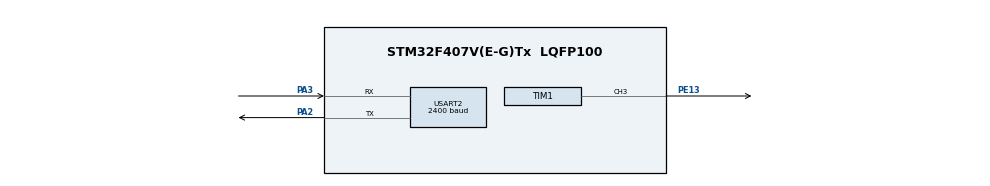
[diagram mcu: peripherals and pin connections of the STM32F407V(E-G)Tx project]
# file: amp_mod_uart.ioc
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Mcu.Family=STM32F4
Mcu.Name=STM32F407V(E-G)Tx
Mcu.Package=LQFP100
NVIC.PriorityGroup=NVIC_PRIORITYGROUP_4
NVIC.TIM1_UP_TIM10_IRQn=true\:0\:0\:true\:false\:true\:true\:true\:true
NVIC.USART2_IRQn=true\:3\:0\:true\:false\:true\:true\:true\:true
PA2.Mode=Asynchronous
PA2.Signal=USART2_TX
PA3.Mode=Asynchronous
PA3.Signal=USART2_RX
PE13.GPIO_Speed=GPIO_SPEED_FREQ_VERY_HIGH
PE13.Signal=S_TIM1_CH3
ProjectManager.HeapSize=0x200
ProjectManager.StackSize=0x400
ProjectManager.TargetToolchain=STM32CubeIDE
RCC.48MHZClocksFreq_Value=84000000
RCC.AHBFreq_Value=168000000
RCC.APB1CLKDivider=RCC_HCLK_DIV4
RCC.APB1Freq_Value=42000000
RCC.APB1TimFreq_Value=84000000
RCC.APB2CLKDivider=RCC_HCLK_DIV2
RCC.APB2Freq_Value=84000000
RCC.APB2TimFreq_Value=168000000
RCC.CortexFreq_Value=168000000
RCC.HCLKFreq_Value=168000000
RCC.HSE_VALUE=25000000
RCC.HSI_VALUE=16000000
RCC.LSE_VALUE=32768
RCC.PLLM=8
RCC.PLLN=168
RCC.SYSCLKFreq_VALUE=168000000
RCC.SYSCLKSource=RCC_SYSCLKSOURCE_PLLCLK
RCC.VCOOutputFreq_Value=336000000
SH.S_TIM1_CH3.0=TIM1_CH3,PWM Generation3 CH3
TIM1.AutoReloadPreload=TIM_AUTORELOAD_PRELOAD_ENABLE
TIM1.Channel-PWM\ Generation3\ CH3=TIM_CHANNEL_3
TIM1.CounterMode=TIM_COUNTERMODE_UP
TIM1.OCFastMode_PWM-PWM\ Generation3\ CH3=TIM_OCFAST_ENABLE
TIM1.Period=23
TIM1.Prescaler=6
TIM1.Pulse-PWM\ Generation3\ CH3=11
TIM1.RepetitionCounter=0
TIM1.TIM_MasterOutputTrigger=TIM_TRGO_RESET
TIM1.TIM_MasterSlaveMode=TIM_MASTERSLAVEMODE_DISABLE
USART2.BaudRate=2400
USART2.VirtualMode=VM_ASYNC
VP_TIM1_VS_ClockSourceINT.Mode=Internal
board=custom

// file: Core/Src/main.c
/* USER CODE BEGIN Header */
/**
  ******************************************************************************
  * @file           : main.c
  * @brief          : Main program body
  ******************************************************************************
  * @attention
  *
  * Copyright (c) 2023 STMicroelectronics.
  * All rights reserved.
  *
  * This software is licensed under terms that can be found in the LICENSE file
  * in the root directory of this software component.
  * If no LICENSE file comes with this software, it is provided AS-IS.
  *
  ******************************************************************************
  */
/* USER CODE END Header */
#include "main.h"

void SystemClock_Config(void);
static void MX_GPIO_Init(void);
static void MX_USART2_UART_Init(void);
static void MX_TIM1_Init(void);

/* USER CODE BEGIN 0 */

int32_t TIM_PERIOD_CNT_100=24;
int32_t TIM_PERIOD_CNT_50=11;
int32_t checkUSART=0;

void TIM1_Callback(void){
  if(LL_GPIO_IsInputPinSet(GPIOA, LL_GPIO_PIN_2)){
    TIM1->CCR3=TIM_PERIOD_CNT_100;
  }else{
	TIM1->CCR3=TIM_PERIOD_CNT_50;
  }
  if(LL_TIM_IsActiveFlag_UPDATE(TIM1)){
    LL_TIM_ClearFlag_UPDATE(TIM1);
  }
}
void  USART2_TX_Callback(void){
  LL_USART_ClearFlag_TC(USART2);
  checkUSART=1;
}

/* USER CODE END 0 */

int main(void)
{
  /* USER CODE BEGIN 1 */
	uint8_t x=0;
  /* USER CODE END 1 */

  /* MCU Configuration--------------------------------------------------------*/

  /* Reset of all peripherals, Initializes the Flash interface and the Systick. */
  LL_APB2_GRP1_EnableClock(LL_APB2_GRP1_PERIPH_SYSCFG);
  LL_APB1_GRP1_EnableClock(LL_APB1_GRP1_PERIPH_PWR);

  /* System interrupt init*/
  NVIC_SetPriorityGrouping(NVIC_PRIORITYGROUP_4);

  /* Configure the system clock */
  SystemClock_Config();

  /* Initialize all configured peripherals */
  MX_GPIO_Init();
  MX_USART2_UART_Init();
  MX_TIM1_Init();
  /* USER CODE BEGIN 2 */

  LL_TIM_EnableARRPreload(TIM1);//Enable automatic loading (ARR) preload
  LL_TIM_OC_EnableFast(TIM1, LL_TIM_CHANNEL_CH3);//Enable fast mode for the output channel
  LL_TIM_CC_EnableChannel(TIM1,LL_TIM_CHANNEL_CH3); //Enable capture/compare channel
  LL_TIM_EnableIT_UPDATE(TIM1);//Enable interrupt
  LL_TIM_EnableAllOutputs(TIM1);//Enable PWM output
  LL_TIM_EnableCounter(TIM1);

  __enable_irq ();
  /* USER CODE END 2 */

  /* Infinite loop */
  /* USER CODE BEGIN WHILE */
  while (1)
  {
	if(checkUSART){
	  checkUSART=0;
	  x++;
	  LL_mDelay(1000);
	}
    LL_USART_TransmitData8(USART2, x);

    /* USER CODE END WHILE */

  }
}

void SystemClock_Config(void)
{
  LL_FLASH_SetLatency(LL_FLASH_LATENCY_5);
  while(LL_FLASH_GetLatency()!= LL_FLASH_LATENCY_5)
  {
  }
  LL_PWR_SetRegulVoltageScaling(LL_PWR_REGU_VOLTAGE_SCALE1);
  LL_RCC_HSI_SetCalibTrimming(16);
  LL_RCC_HSI_Enable();

   /* Wait till HSI is ready */
  while(LL_RCC_HSI_IsReady() != 1)
  {

  }
  LL_RCC_PLL_ConfigDomain_SYS(LL_RCC_PLLSOURCE_HSI, LL_RCC_PLLM_DIV_8, 168, LL_RCC_PLLP_DIV_2);
  LL_RCC_PLL_Enable();

   /* Wait till PLL is ready */
  while(LL_RCC_PLL_IsReady() != 1)
  {

  }
  LL_RCC_SetAHBPrescaler(LL_RCC_SYSCLK_DIV_1);
  LL_RCC_SetAPB1Prescaler(LL_RCC_APB1_DIV_4);
  LL_RCC_SetAPB2Prescaler(LL_RCC_APB2_DIV_2);
  LL_RCC_SetSysClkSource(LL_RCC_SYS_CLKSOURCE_PLL);

   /* Wait till System clock is ready */
  while(LL_RCC_GetSysClkSource() != LL_RCC_SYS_CLKSOURCE_STATUS_PLL)
  {

  }
  LL_Init1msTick(168000000);
  LL_SetSystemCoreClock(168000000);
}

static void MX_TIM1_Init(void)
{

  /* USER CODE BEGIN TIM1_Init 0 */
	//TIM1->CCR1=TIM1->ARR/2;

  /* USER CODE END TIM1_Init 0 */

  LL_TIM_InitTypeDef TIM_InitStruct = {0};
  LL_TIM_OC_InitTypeDef TIM_OC_InitStruct = {0};
  LL_TIM_BDTR_InitTypeDef TIM_BDTRInitStruct = {0};

  LL_GPIO_InitTypeDef GPIO_InitStruct = {0};

  /* Peripheral clock enable */
  LL_APB2_GRP1_EnableClock(LL_APB2_GRP1_PERIPH_TIM1);

  /* TIM1 interrupt Init */
  NVIC_SetPriority(TIM1_UP_TIM10_IRQn, NVIC_EncodePriority(NVIC_GetPriorityGrouping(),0, 0));
  NVIC_EnableIRQ(TIM1_UP_TIM10_IRQn);

  TIM_InitStruct.Prescaler = 6;
  TIM_InitStruct.CounterMode = LL_TIM_COUNTERMODE_UP;
  TIM_InitStruct.Autoreload = 23;
  TIM_InitStruct.ClockDivision = LL_TIM_CLOCKDIVISION_DIV1;
  TIM_InitStruct.RepetitionCounter = 0;
  LL_TIM_Init(TIM1, &TIM_InitStruct);
  LL_TIM_EnableARRPreload(TIM1);
  LL_TIM_SetClockSource(TIM1, LL_TIM_CLOCKSOURCE_INTERNAL);
  LL_TIM_OC_EnablePreload(TIM1, LL_TIM_CHANNEL_CH3);
  TIM_OC_InitStruct.OCMode = LL_TIM_OCMODE_PWM1;
  TIM_OC_InitStruct.OCState = LL_TIM_OCSTATE_DISABLE;
  TIM_OC_InitStruct.OCNState = LL_TIM_OCSTATE_DISABLE;
  TIM_OC_InitStruct.CompareValue = 11;
  TIM_OC_InitStruct.OCPolarity = LL_TIM_OCPOLARITY_HIGH;
  TIM_OC_InitStruct.OCNPolarity = LL_TIM_OCPOLARITY_HIGH;
  TIM_OC_InitStruct.OCIdleState = LL_TIM_OCIDLESTATE_LOW;
  TIM_OC_InitStruct.OCNIdleState = LL_TIM_OCIDLESTATE_LOW;
  LL_TIM_OC_Init(TIM1, LL_TIM_CHANNEL_CH3, &TIM_OC_InitStruct);
  LL_TIM_OC_EnableFast(TIM1, LL_TIM_CHANNEL_CH3);
  LL_TIM_SetTriggerOutput(TIM1, LL_TIM_TRGO_RESET);
  LL_TIM_DisableMasterSlaveMode(TIM1);
  TIM_BDTRInitStruct.OSSRState = LL_TIM_OSSR_DISABLE;
  TIM_BDTRInitStruct.OSSIState = LL_TIM_OSSI_DISABLE;
  TIM_BDTRInitStruct.LockLevel = LL_TIM_LOCKLEVEL_OFF;
  TIM_BDTRInitStruct.DeadTime = 0;
  TIM_BDTRInitStruct.BreakState = LL_TIM_BREAK_DISABLE;
  TIM_BDTRInitStruct.BreakPolarity = LL_TIM_BREAK_POLARITY_HIGH;
  TIM_BDTRInitStruct.AutomaticOutput = LL_TIM_AUTOMATICOUTPUT_DISABLE;
  LL_TIM_BDTR_Init(TIM1, &TIM_BDTRInitStruct);
  LL_AHB1_GRP1_EnableClock(LL_AHB1_GRP1_PERIPH_GPIOE);
  /**TIM1 GPIO Configuration
  PE13   ------> TIM1_CH3
  */
  GPIO_InitStruct.Pin = LL_GPIO_PIN_13;
  GPIO_InitStruct.Mode = LL_GPIO_MODE_ALTERNATE;
  GPIO_InitStruct.Speed = LL_GPIO_SPEED_FREQ_VERY_HIGH;
  GPIO_InitStruct.OutputType = LL_GPIO_OUTPUT_PUSHPULL;
  GPIO_InitStruct.Pull = LL_GPIO_PULL_NO;
  GPIO_InitStruct.Alternate = LL_GPIO_AF_1;
  LL_GPIO_Init(GPIOE, &GPIO_InitStruct);

}

static void MX_USART2_UART_Init(void)
{

  LL_USART_InitTypeDef USART_InitStruct = {0};

  LL_GPIO_InitTypeDef GPIO_InitStruct = {0};

  /* Peripheral clock enable */
  LL_APB1_GRP1_EnableClock(LL_APB1_GRP1_PERIPH_USART2);

  LL_AHB1_GRP1_EnableClock(LL_AHB1_GRP1_PERIPH_GPIOA);
  /**USART2 GPIO Configuration
  PA2   ------> USART2_TX
  PA3   ------> USART2_RX
  */
  GPIO_InitStruct.Pin = LL_GPIO_PIN_2|LL_GPIO_PIN_3;
  GPIO_InitStruct.Mode = LL_GPIO_MODE_ALTERNATE;
  GPIO_InitStruct.Speed = LL_GPIO_SPEED_FREQ_VERY_HIGH;
  GPIO_InitStruct.OutputType = LL_GPIO_OUTPUT_PUSHPULL;
  GPIO_InitStruct.Pull = LL_GPIO_PULL_NO;
  GPIO_InitStruct.Alternate = LL_GPIO_AF_7;
  LL_GPIO_Init(GPIOA, &GPIO_InitStruct);

  /* USART2 interrupt Init */
  NVIC_SetPriority(USART2_IRQn, NVIC_EncodePriority(NVIC_GetPriorityGrouping(),3, 0));
  NVIC_EnableIRQ(USART2_IRQn);

  USART_InitStruct.BaudRate = 2400;
  USART_InitStruct.DataWidth = LL_USART_DATAWIDTH_8B;
  USART_InitStruct.StopBits = LL_USART_STOPBITS_1;
  USART_InitStruct.Parity = LL_USART_PARITY_NONE;
  USART_InitStruct.TransferDirection = LL_USART_DIRECTION_TX_RX;
  USART_InitStruct.HardwareFlowControl = LL_USART_HWCONTROL_NONE;
  USART_InitStruct.OverSampling = LL_USART_OVERSAMPLING_16;
  LL_USART_Init(USART2, &USART_InitStruct);
  LL_USART_ConfigAsyncMode(USART2);
  LL_USART_Enable(USART2);

}

static void MX_GPIO_Init(void)
{

  /* GPIO Ports Clock Enable */
  LL_AHB1_GRP1_EnableClock(LL_AHB1_GRP1_PERIPH_GPIOA);
  LL_AHB1_GRP1_EnableClock(LL_AHB1_GRP1_PERIPH_GPIOE);

}

void Error_Handler(void)
{
  __disable_irq();
  while (1)
  {
  }
}
